# CY8C4xxx register map
File version: 0.1
Registers are 8-bit, read-write, no defined reset value unless marked. A register's access mark holds for its fields unless they carry their own. Offsets are from the block's base; [hi:lo] are bit positions.

## CTBM — Continuous Time Block Mini
Base 0x40100000
0x00 CTB_CTRL 32-bit — global CTB and power control
  [31] ENABLED — - 0: CTB IP disabled (put analog in power down, open all switches)?- 1: CTB IP enabled
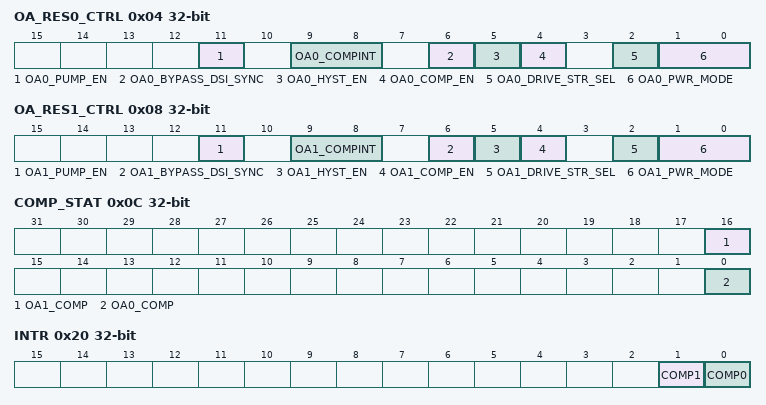
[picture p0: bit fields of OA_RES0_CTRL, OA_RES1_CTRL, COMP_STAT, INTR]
0x04 OA_RES0_CTRL 32-bit — Opamp0 and resistor0 control
  [11] OA0_PUMP_EN — Opamp0 pump enable
  [9:8] OA0_COMPINT — Opamp0 comparator edge detect
    0=DISABLE; 1=RISING; 2=FALLING; 3=BOTH
  [6] OA0_BYPASS_DSI_SYNC — Opamp0 bypass comparator output synchronization for DSI output: 0=synchronize, 1=bypass
  [5] OA0_HYST_EN — Opamp0 hysteresis enable (10mV)
  [4] OA0_COMP_EN — Opamp0 comparator enable
  [2] OA0_DRIVE_STR_SEL — Opamp0 output strenght select 0=1x, 1=10x
  [1:0] OA0_PWR_MODE — Opamp0 power level: 0=off
0x08 OA_RES1_CTRL 32-bit — Opamp1 and resistor1 control
  [11] OA1_PUMP_EN — Opamp1 pump enable
  [9:8] OA1_COMPINT — Opamp0 comparator edge detect
    0=DISABLE; 1=RISING; 2=FALLING; 3=BOTH
  [6] OA1_BYPASS_DSI_SYNC — Opamp1 bypass comparator output synchronization for DSI output: 0=synchronize, 1=bypass
  [5] OA1_HYST_EN — Opamp1 hysteresis enable (10mV)
  [4] OA1_COMP_EN — Opamp1 comparator enable
  [2] OA1_DRIVE_STR_SEL — Opamp1 output strenght select 0=1x, 1=10x
  [1:0] OA1_PWR_MODE — Opamp1 power level: 0=off
0x0C COMP_STAT 32-bit — Comparator status
  [16] OA1_COMP ro — Opamp1 current comparator status
  [0] OA0_COMP ro — Opamp0 current comparator status
0x20 INTR 32-bit — Interrupt request register
  [1] COMP1 write-once — Comparator 1 Interrupt: hardware sets this interrupt when comparator 1 triggers. Write with '1' to clear bit.
  [0] COMP0 write-once — Comparator 0 Interrupt: hardware sets this interrupt when comparator 0 triggers. Write with '1' to clear bit.
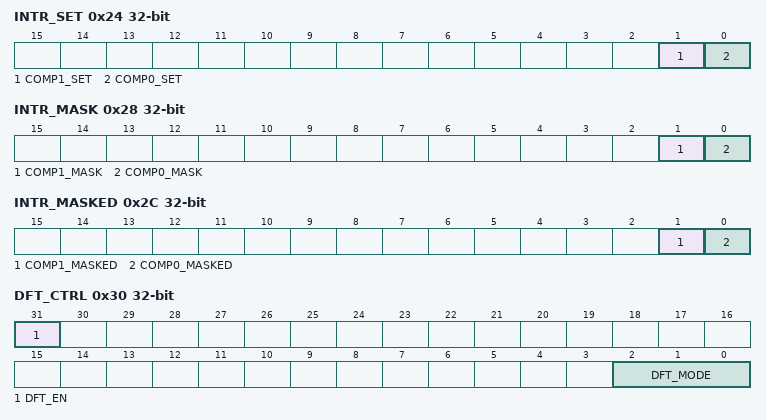
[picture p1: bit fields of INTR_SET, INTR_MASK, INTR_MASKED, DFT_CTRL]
0x24 INTR_SET 32-bit — Interrupt request set register
  [1] COMP1_SET write-once — Write with '1' to set corresponding bit in interrupt request register.
  [0] COMP0_SET write-once — Write with '1' to set corresponding bit in interrupt request register.
0x28 INTR_MASK 32-bit — Interrupt request mask
  [1] COMP1_MASK — Mask bit for corresponding bit in interrupt request register.
  [0] COMP0_MASK — Mask bit for corresponding bit in interrupt request register.
0x2C INTR_MASKED 32-bit — Interrupt request masked
  [1] COMP1_MASKED ro — Logical and of corresponding request and mask bits.
  [0] COMP0_MASKED ro — Logical and of corresponding request and mask bits.
0x30 DFT_CTRL 32-bit — Analog DfT controls
  [31] DFT_EN — Analog DfT enable
  [2:0] DFT_MODE — Analog DfT mode
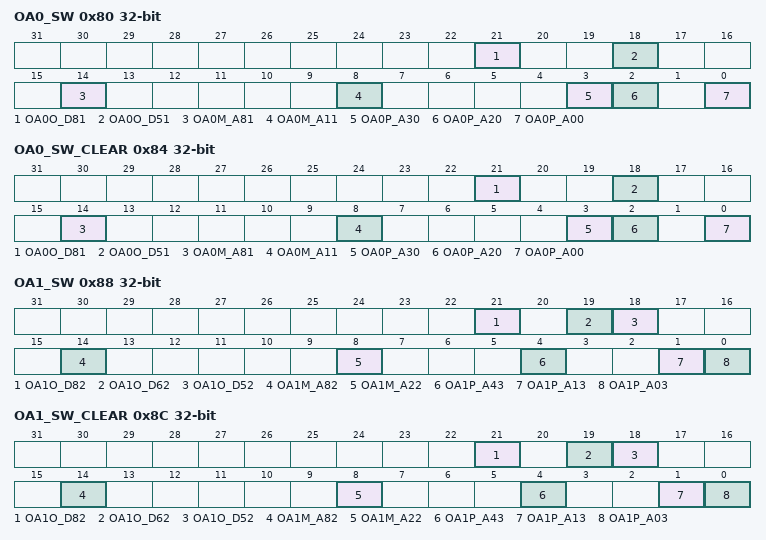
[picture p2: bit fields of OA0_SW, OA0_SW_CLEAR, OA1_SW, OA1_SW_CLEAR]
0x80 OA0_SW 32-bit — Opamp0 switch control
  [21] OA0O_D81 write-once — Opamp0 output switch to short 1x with 10x drive
  [18] OA0O_D51 write-once — Opamp0 output sarbus0 (ctbbus2 in CTB)
  [14] OA0M_A81 write-once — Opamp0 negative terminal Opamp0 bottom
  [8] OA0M_A11 write-once — Opamp0 negative terminal P1
  [3] OA0P_A30 write-once — Opamp0 positive terminal ctbbus0
  [2] OA0P_A20 write-once — Opamp0 positive terminal P0
  [0] OA0P_A00 write-once — Opamp0 positive terminal amuxbusa
0x84 OA0_SW_CLEAR 32-bit — Opamp0 switch control clear
  [21] OA0O_D81 write-once — see corresponding bit in OA0_SW
  [18] OA0O_D51 write-once — see corresponding bit in OA0_SW
  [14] OA0M_A81 write-once — see corresponding bit in OA0_SW
  [8] OA0M_A11 write-once — see corresponding bit in OA0_SW
  [3] OA0P_A30 write-once — see corresponding bit in OA0_SW
  [2] OA0P_A20 write-once — see corresponding bit in OA0_SW
  [0] OA0P_A00 write-once — see corresponding bit in OA0_SW
0x88 OA1_SW 32-bit — Opamp1 switch control
  [21] OA1O_D82 write-once — Opamp1 output switch to short 1x with 10x drive
  [19] OA1O_D62 write-once — Opamp1 output sarbus1 (ctbbus3 in CTB)
  [18] OA1O_D52 write-once — Opamp1 output sarbus0 (ctbbus2 in CTB)
  [14] OA1M_A82 write-once — Opamp1 negative terminal Opamp1 bottom
  [8] OA1M_A22 write-once — Opamp1 negative terminal P4
  [4] OA1P_A43 write-once — Opamp1 positive terminal ctbbus1
  [1] OA1P_A13 write-once — Opamp1 positive terminal P5
  [0] OA1P_A03 write-once — Opamp1 positive terminal amuxbusb
0x8C OA1_SW_CLEAR 32-bit — Opamp1 switch control clear
  [21] OA1O_D82 write-once — see corresponding bit in OA1_SW
  [19] OA1O_D62 write-once — see corresponding bit in OA1_SW
  [18] OA1O_D52 write-once — see corresponding bit in OA1_SW
  [14] OA1M_A82 write-once — see corresponding bit in OA1_SW
  [8] OA1M_A22 write-once — see corresponding bit in OA1_SW
  [4] OA1P_A43 write-once — see corresponding bit in OA1_SW
  [1] OA1P_A13 write-once — see corresponding bit in OA1_SW
  [0] OA1P_A03 write-once — see corresponding bit in OA1_SW
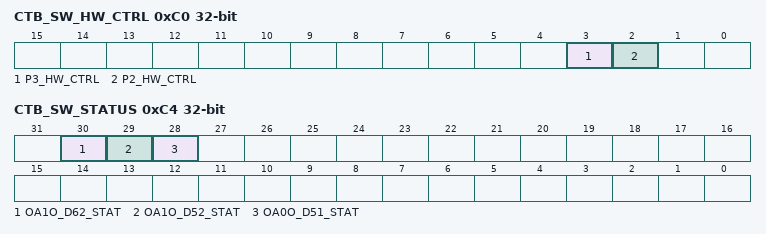
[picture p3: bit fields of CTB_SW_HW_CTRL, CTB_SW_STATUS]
0xC0 CTB_SW_HW_CTRL 32-bit — CTB bus switch control status
  [3] P3_HW_CTRL — Pin P3 switches
  [2] P2_HW_CTRL — Pin P2 switches
0xC4 CTB_SW_STATUS 32-bit — CTB bus switch control status
  [30] OA1O_D62_STAT ro — see OA1O_D62 bit in OA1_SW
  [29] OA1O_D52_STAT ro — see OA1O_D52 bit in OA1_SW
  [28] OA0O_D51_STAT ro — see OA0O_D51 bit in OA0_SW
0xF00 OA0_OFFSET_TRIM 32-bit — Opamp0 trim control
  [5:0] OA0_OFFSET_TRIM — Opamp0 offset trim
0xF04 OA0_SLOPE_OFFSET_TRIM 32-bit — Opamp0 trim control
  [5:0] OA0_SLOPE_OFFSET_TRIM — Opamp0 slope offset drift trim
0xF08 OA0_COMP_TRIM 32-bit — Opamp0 trim control
  [1:0] OA0_COMP_TRIM — Opamp0 Compenation Capacitor Trim
0xF0C OA1_OFFSET_TRIM 32-bit — Opamp1 trim control
  [5:0] OA1_OFFSET_TRIM — Opamp1 offset trim
0xF10 OA1_SLOPE_OFFSET_TRIM 32-bit — Opamp1 trim control
  [5:0] OA1_SLOPE_OFFSET_TRIM — Opamp1 slope offset drift trim
0xF14 OA1_COMP_TRIM 32-bit — Opamp1 trim control
  [1:0] OA1_COMP_TRIM — Opamp1 Compenation Capacitor Trim
